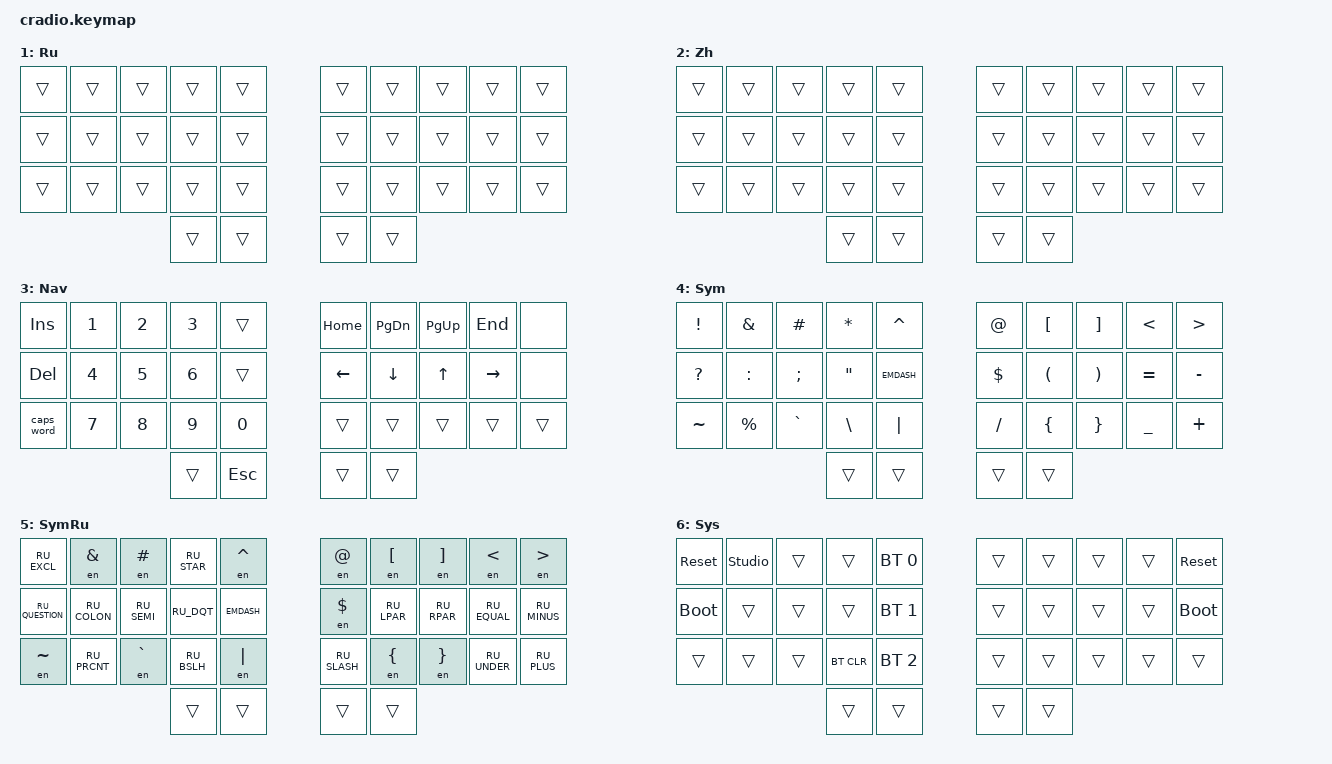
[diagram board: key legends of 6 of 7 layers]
// Ferris Sweep (cradio). Схема слоёв: keymap-drawer/cradio.svg. Тренировки: TRAINING.md.
// На маке три раскладки: ABC, «Russian – PC», «Пиньинь – упрощённый».
// Язык выбирает Karabiner по клавишам F18 (ABC), F19 (русская), F20 (пиньинь): karabiner/lang.json.
// Отвергнуто: LANG2 (英数) и GLOBE (🌐) из прошивки. Проверено 2026-10-22, macOS на них не переключает раскладку.

#include <behaviors.dtsi>
#include <dt-bindings/zmk/keys.h>
#include <dt-bindings/zmk/bt.h>
#include "keys_ru.h"

// Слои. RU и ZH не содержат клавиш: это флаги «на маке включён русский / китайский».
// Включён ровно один из BASE, RU, ZH: их выставляет только &to в макросах выбора языка.
#define BASE  0
#define RU    1
#define ZH    2
#define NAV   3
#define SYM   4
#define SYMRU 5
#define SYS   6

// Позиции клавиш: левая рука, правая рука, большие пальцы.
#define KEYS_L 0 1 2 3 4 10 11 12 13 14 20 21 22 23 24
#define KEYS_R 5 6 7 8 9 15 16 17 18 19 25 26 27 28 29
#define THUMBS 30 31 32 33

// Модификаторы на домашнем ряду: мизинец Shift, безымянный Ctrl, средний Alt, указательный Cmd.
#define HRML(k1,k2,k3,k4) &hml LSHFT k1  &hml LCTRL k2  &hml LALT k3  &hml LGUI k4
#define HRMR(k1,k2,k3,k4) &hmr RGUI k1  &hmr RALT k2  &hmr RCTRL k3  &hmr RSHFT k4

#define LANG_EN F18
#define LANG_RU F19
#define LANG_ZH F20
#define EMDASH      LA(LS(MINUS)) // длинное тире: Option+Shift+минус

/ {
    behaviors {
        hml: homerow_mods_left {
            compatible = "zmk,behavior-hold-tap";
            #binding-cells = <2>;
            flavor = "balanced";
            tapping-term-ms = <280>;
            quick-tap-ms = <175>;
            require-prior-idle-ms = <150>;
            bindings = <&kp>, <&kp>;
            // Модификатор включается, только если следующая клавиша на другой руке.
            hold-trigger-key-positions = <KEYS_R THUMBS>;
            hold-trigger-on-release;
        };
        hmr: homerow_mods_right {
            compatible = "zmk,behavior-hold-tap";
            #binding-cells = <2>;
            flavor = "balanced";
            tapping-term-ms = <280>;
            quick-tap-ms = <175>;
            require-prior-idle-ms = <150>;
            bindings = <&kp>, <&kp>;
            hold-trigger-key-positions = <KEYS_L THUMBS>;
            hold-trigger-on-release;
        };
    };

    macros {
        // Выбор языка: клавиша для Karabiner и флаг прошивки.
        lang_en: lang_en {
            compatible = "zmk,behavior-macro";
            #binding-cells = <0>;
            wait-ms = <0>;
            tap-ms = <20>;
            bindings = <&macro_tap &kp LANG_EN &to BASE>;
        };
        lang_ru: lang_ru {
            compatible = "zmk,behavior-macro";
            #binding-cells = <0>;
            wait-ms = <0>;
            tap-ms = <20>;
            bindings = <&macro_tap &kp LANG_RU &to RU>;
        };
        lang_zh: lang_zh {
            compatible = "zmk,behavior-macro";
            #binding-cells = <0>;
            wait-ms = <0>;
            tap-ms = <20>;
            bindings = <&macro_tap &kp LANG_ZH &to ZH>;
        };
        // Знак, которого нет в русской раскладке: переключиться на английский, подождать, напечатать.
        // Здесь &tog RU, а не &to BASE: &to выключил бы и удерживаемый слой Sym.
        en: to_english {
            compatible = "zmk,behavior-macro-one-param";
            #binding-cells = <1>;
            wait-ms = <0>;
            tap-ms = <20>;
            bindings
                = <&macro_tap &kp LANG_EN>
                , <&macro_wait_time 80>
                , <&macro_tap &tog RU>
                , <&macro_param_1to1>
                , <&macro_tap &kp MACRO_PLACEHOLDER>
                ;
        };
    };

    combos {
        compatible = "zmk,combos";
        // Язык: пробел+Enter (внутренние клавиши) переключает английский и русский, из китайского ведёт в английский.
        combo_lang_ru  { timeout-ms = <50>; key-positions = <31 32>; bindings = <&lang_ru>;      layers = <BASE>; };
        combo_lang_en  { timeout-ms = <50>; key-positions = <31 32>; bindings = <&lang_en>;      layers = <RU ZH>; };
        // Китайский: Tab+пробел, обе клавиши под левым большим пальцем.
        combo_lang_zh  { timeout-ms = <50>; key-positions = <30 31>; bindings = <&lang_zh>;      layers = <BASE RU ZH>; };
        // Вертикальные комбо: один палец жмёт две клавиши столбца. Буквы только в русском режиме.
        combo_yo       { timeout-ms = <50>; key-positions = <4 14>;  bindings = <&kp GRAVE>;     layers = <RU>; };   // T+G -> ё
        combo_hard     { timeout-ms = <50>; key-positions = <16 26>; bindings = <&kp RBKT>;      layers = <RU>; };   // J+M -> ъ
        combo_kha      { timeout-ms = <50>; key-positions = <9 19>;  bindings = <&kp LBKT>;      layers = <RU>; };   // P+' -> х
        combo_comma_en { timeout-ms = <50>; key-positions = <18 28>; bindings = <&kp COMMA>;     layers = <BASE ZH>; }; // L+. -> ,
        combo_comma_ru { timeout-ms = <50>; key-positions = <18 28>; bindings = <&kp RU_COMMA>;  layers = <RU>; };
    };

    conditional_layers {
        compatible = "zmk,conditional-layers";
        sym_ru { if-layers = <RU SYM>;  then-layer = <SYMRU>; };
        system { if-layers = <NAV SYM>; then-layer = <SYS>; };
    };

    keymap {
        compatible = "zmk,keymap";

        base_layer {
            display-name = "Base";
            bindings = <
            &kp Q      &kp W      &kp E      &kp R      &kp T          &kp Y      &kp U      &kp I      &kp O      &kp P
            HRML(A,        S,         D,         F)     &kp G          &kp H      HRMR(J,        K,         L,        SQT)
            &kp Z      &kp X      &kp C      &kp V      &kp B          &kp N      &kp M      &kp COMMA  &kp DOT    &kp FSLH
                                            &lt SYM TAB &kp SPACE     &kp ENTER  &lt NAV BSPC
            >;
        };

        ru_flag {
            display-name = "Ru";
            bindings = <
            &trans     &trans     &trans     &trans     &trans         &trans     &trans     &trans     &trans     &trans
            &trans     &trans     &trans     &trans     &trans         &trans     &trans     &trans     &trans     &trans
            &trans     &trans     &trans     &trans     &trans         &trans     &trans     &trans     &trans     &trans
                                             &trans     &trans         &trans     &trans
            >;
        };

        zh_flag {
            display-name = "Zh";
            bindings = <
            &trans     &trans     &trans     &trans     &trans         &trans     &trans     &trans     &trans     &trans
            &trans     &trans     &trans     &trans     &trans         &trans     &trans     &trans     &trans     &trans
            &trans     &trans     &trans     &trans     &trans         &trans     &trans     &trans     &trans     &trans
                                             &trans     &trans         &trans     &trans
            >;
        };

        nav_layer {
            display-name = "Nav";
            bindings = <
            &kp INS    &kp N1     &kp N2     &kp N3     &trans         &kp HOME   &kp PG_DN  &kp PG_UP  &kp END    &none
            &kp DEL    &kp N4     &kp N5     &kp N6     &trans         &kp LEFT   &kp DOWN   &kp UP     &kp RIGHT  &none
           &caps_word  &kp N7     &kp N8     &kp N9     &kp N0         &trans     &trans     &trans     &trans     &trans
                                             &trans     &kp ESC        &trans     &trans
            >;
        };

        sym_layer {
            display-name = "Sym";
            bindings = <
            &kp EXCL   &kp AMPS   &kp HASH   &kp ASTRK  &kp CARET      &kp AT     &kp LBKT   &kp RBKT   &kp LT     &kp GT
            &kp QMARK  &kp COLON  &kp SEMI   &kp DQT    &kp EMDASH     &kp DLLR   &kp LPAR   &kp RPAR   &kp EQUAL  &kp MINUS
            &kp TILDE  &kp PRCNT  &kp GRAVE  &kp BSLH   &kp PIPE       &kp FSLH   &kp LBRC   &kp RBRC   &kp UNDER  &kp PLUS
                                             &trans     &trans         &trans     &trans
            >;
        };

        // Тот же слой для русского режима. &en: знака нет в русской раскладке, сначала переключение на английский.
        sym_ru_layer {
            display-name = "SymRu";
            bindings = <
            &kp RU_EXCL &en AMPS  &en HASH   &kp RU_STAR &en CARET     &en AT     &en LBKT   &en RBKT   &en LT     &en GT
          &kp RU_QUESTION &kp RU_COLON &kp RU_SEMI &kp RU_DQT &kp EMDASH &en DLLR &kp RU_LPAR &kp RU_RPAR &kp RU_EQUAL &kp RU_MINUS
            &en TILDE  &kp RU_PRCNT &en GRAVE &kp RU_BSLH &en PIPE     &kp RU_SLASH &en LBRC &en RBRC   &kp RU_UNDER &kp RU_PLUS
                                             &trans     &trans         &trans     &trans
            >;
        };

        sys_layer {
            display-name = "Sys";
            bindings = <
           &sys_reset &studio_unlock &trans    &trans    &bt BT_SEL 0    &trans     &trans     &trans     &trans    &sys_reset
          &bootloader  &trans     &trans     &trans    &bt BT_SEL 1    &trans     &trans     &trans     &trans    &bootloader
            &trans     &trans     &trans    &bt BT_CLR &bt BT_SEL 2    &trans     &trans     &trans     &trans     &trans
                                             &trans     &trans         &trans     &trans
            >;
        };
    };
};
